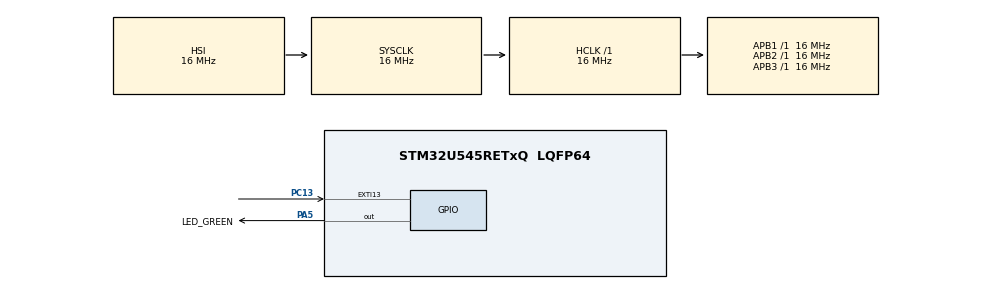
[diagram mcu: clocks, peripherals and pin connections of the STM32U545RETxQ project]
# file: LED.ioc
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CORTEX_M33_NS.userName=CORTEX_M33
Mcu.Family=STM32U5
Mcu.Name=STM32U545RETxQ
Mcu.Package=LQFP64
NVIC.EXTI13_IRQn=true\:0\:0\:false\:false\:true\:true\:true\:true
NVIC.PVD_PVM_IRQn=true\:0\:0\:false\:false\:true\:true\:true\:true
NVIC.PriorityGroup=NVIC_PRIORITYGROUP_4
NVIC.RTC_IRQn=true\:0\:0\:false\:false\:true\:true\:true\:true
PA5.GPIO_Label=LED_GREEN
PA5.GPIO_PuPd=GPIO_PULLUP
PA5.GPIO_Speed=GPIO_SPEED_FREQ_HIGH
PA5.Signal=GPIO_Output
PC13.Signal=GPXTI13
PC14-OSC32_IN\ (PC14).Mode=LSE-External-Oscillator
PC14-OSC32_IN\ (PC14).Signal=RCC_OSC32_IN
PC15-OSC32_OUT\ (PC15).Mode=LSE-External-Oscillator
PC15-OSC32_OUT\ (PC15).Signal=RCC_OSC32_OUT
PWR.PowerMode=PWR_SMPS_SUPPLY
ProjectManager.HeapSize=0x200
ProjectManager.StackSize=0x400
ProjectManager.TargetToolchain=STM32CubeIDE
RCC.ADCFreq_Value=16000000
RCC.AHBFreq_Value=16000000
RCC.APB1Freq_Value=16000000
RCC.APB1TimFreq_Value=16000000
RCC.APB2Freq_Value=16000000
RCC.APB2TimFreq_Value=16000000
RCC.APB3Freq_Value=16000000
RCC.CortexFreq_Value=16000000
RCC.DACCLockSelectionVirtual=RCC_DAC1CLKSOURCE_LSI
RCC.DACCLockSelectionVirtualString=RCC_DAC1CLKSOURCE_LSI
RCC.EPOD_VALUE=4000000
RCC.HCLKFreq_Value=16000000
RCC.HSE_VALUE=16000000
RCC.HSI48_VALUE=48000000
RCC.HSI_VALUE=16000000
RCC.LSIDIV_VALUE=32000
RCC.MSI_VALUE=4000000
RCC.RTCClockSelection=RCC_RTCCLKSOURCE_LSE
RCC.SYSCLKFreq_VALUE=16000000
RCC.SYSCLKSource=RCC_SYSCLKSOURCE_HSI
RCC.USBFreq_Value=48000000
RCC.VCOOutputFreq_Value=516000000
RTC.Alarm-Alarm\ A=RTC_ALARM_A
RTC.AlarmMaskDateWeekDay-Alarm\ A=RTC_ALARMMASK_DATEWEEKDAY
RTC.AlarmMaskHours-Alarm\ A=RTC_ALARMMASK_HOURS
RTC.AlarmMaskMinutes-Alarm\ A=RTC_ALARMMASK_MINUTES
RTC.Format=RTC_FORMAT_BCD
RTC.Seconds_A-Alarm\ A=10
RTC.rtcPrivilegeFull=RTC_PRIVILEGE_FULL_NO
VP_ICACHE_VS_ICACHE.Mode=DirectMappedCache
VP_LPBAMQUEUE_VS_QUEUE.Mode=QUEUEMODE
VP_LPBAM_VS_SIG1.Mode=SmartRun
VP_LPBAM_VS_SIG4.Mode=LPDMA1
VP_MEMORYMAP_VS_MEMORYMAP.Mode=CurAppReg
VP_PWR_VS_LPOM.Mode=PowerOptimisation
VP_PWR_VS_SECSignals.Mode=Security/Privilege
VP_RTC_VS_RTC_Activate.Mode=RTC_Enabled
VP_RTC_VS_RTC_Alarm_A_Intern.Mode=Alarm A
VP_RTC_VS_RTC_Calendar.Mode=RTC_Calendar
board=NUCLEO-U545RE-Q

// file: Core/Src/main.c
/* USER CODE BEGIN Header */
/**
 ******************************************************************************
 * @file           : main.c
 * @brief          : Main program body
 ******************************************************************************
 * @attention
 *
 * Copyright (c) 2024 STMicroelectronics.
 * All rights reserved.
 *
 * This software is licensed under terms that can be found in the LICENSE file
 * in the root directory of this software component.
 * If no LICENSE file comes with this software, it is provided AS-IS.
 *
 ******************************************************************************
 */
/* USER CODE END Header */
#include "main.h"
#include "icache.h"
#include "memorymap.h"
#include "rtc.h"
#include "gpio.h"

/* USER CODE BEGIN Includes */
#include "stdio.h"
/* USER CODE END Includes */

void SystemClock_Config(void);
static void SystemPower_Config(void);
/* USER CODE BEGIN PFP */
//void HAL_RTCEx_AlarmBEventCallback(RTC_HandleTypeDef *hrtc)
//{
//	HAL_ResumeTick();
//}
/* USER CODE END PFP */

/* USER CODE BEGIN 0 */
void Enter_Shutdown_Mode(void) {
	// Ensure all wakeup flags are cleared
	PWR->WUSCR |= PWR_WUSCR_CWUF;

	// Enable Wakeup pin (WKUP1) as wakeup source
	PWR->WUCR1 |= PWR_WUCR1_WUPEN2;

	// Select Shutdown mode in power control register
	PWR->CR1 &= ~PWR_CR1_LPMS;
	PWR->CR1 |= (0b11 << PWR_CR1_LPMS_Pos);

	// Set the SLEEPDEEP bit in Cortex System Control Register
	SCB->SCR |= SCB_SCR_SLEEPDEEP_Msk;

	// Request Wait For Interrupt
	__WFI();
}
/* USER CODE END 0 */

int main(void)
{

  /* MCU Configuration--------------------------------------------------------*/

  /* Reset of all peripherals, Initializes the Flash interface and the Systick. */
  HAL_Init();

  /* Configure the system clock */
  SystemClock_Config();

  /* Configure the System Power */
  SystemPower_Config();

  /* Initialize all configured peripherals */
  MX_GPIO_Init();
  MX_ICACHE_Init();
  MX_RTC_Init();
  /* USER CODE BEGIN 2 */

	HAL_GPIO_WritePin(LED_GREEN_GPIO_Port, LED_GREEN_Pin, SET);
	HAL_Delay(100);
	HAL_GPIO_WritePin(LED_GREEN_GPIO_Port, LED_GREEN_Pin, RESET);
	HAL_Delay(100);
	HAL_GPIO_WritePin(LED_GREEN_GPIO_Port, LED_GREEN_Pin, SET);
	HAL_Delay(100);
	HAL_GPIO_WritePin(LED_GREEN_GPIO_Port, LED_GREEN_Pin, RESET);
	HAL_Delay(100);

  /* USER CODE END 2 */

  /* Infinite loop */
	while (1) {

    /* USER CODE BEGIN 3 */
		HAL_Delay(100);
//		printf("Going to Sleep Mode\r\n");
		HAL_SuspendTick();
		Enter_Shutdown_Mode();
		HAL_ResumeTick();
		SystemClock_Config();
		HAL_Delay(100);
//		printf("Wakeup from sleep mode\r\n");
		HAL_GPIO_TogglePin(LED_GREEN_GPIO_Port, LED_GREEN_Pin);
		HAL_Delay(100);
		HAL_GPIO_TogglePin(LED_GREEN_GPIO_Port, LED_GREEN_Pin);
		HAL_Delay(100);
		HAL_GPIO_TogglePin(LED_GREEN_GPIO_Port, LED_GREEN_Pin);
		HAL_Delay(100);
		HAL_GPIO_TogglePin(LED_GREEN_GPIO_Port, LED_GREEN_Pin);
		HAL_Delay(100);
	}
  /* USER CODE END 3 */
}

void SystemClock_Config(void)
{
  RCC_OscInitTypeDef RCC_OscInitStruct = {0};
  RCC_ClkInitTypeDef RCC_ClkInitStruct = {0};

  /** Configure the main internal regulator output voltage
  */
  if (HAL_PWREx_ControlVoltageScaling(PWR_REGULATOR_VOLTAGE_SCALE4) != HAL_OK)
  {
    Error_Handler();
  }

  /** Configure LSE Drive Capability
  */
  HAL_PWR_EnableBkUpAccess();
  __HAL_RCC_LSEDRIVE_CONFIG(RCC_LSEDRIVE_LOW);

  /** Initializes the CPU, AHB and APB buses clocks
  */
  RCC_OscInitStruct.OscillatorType = RCC_OSCILLATORTYPE_HSI|RCC_OSCILLATORTYPE_LSE;
  RCC_OscInitStruct.LSEState = RCC_LSE_ON;
  RCC_OscInitStruct.HSIState = RCC_HSI_ON;
  RCC_OscInitStruct.HSICalibrationValue = RCC_HSICALIBRATION_DEFAULT;
  RCC_OscInitStruct.PLL.PLLState = RCC_PLL_NONE;
  if (HAL_RCC_OscConfig(&RCC_OscInitStruct) != HAL_OK)
  {
    Error_Handler();
  }

  /** Initializes the CPU, AHB and APB buses clocks
  */
  RCC_ClkInitStruct.ClockType = RCC_CLOCKTYPE_HCLK|RCC_CLOCKTYPE_SYSCLK
                              |RCC_CLOCKTYPE_PCLK1|RCC_CLOCKTYPE_PCLK2
                              |RCC_CLOCKTYPE_PCLK3;
  RCC_ClkInitStruct.SYSCLKSource = RCC_SYSCLKSOURCE_HSI;
  RCC_ClkInitStruct.AHBCLKDivider = RCC_SYSCLK_DIV1;
  RCC_ClkInitStruct.APB1CLKDivider = RCC_HCLK_DIV1;
  RCC_ClkInitStruct.APB2CLKDivider = RCC_HCLK_DIV1;
  RCC_ClkInitStruct.APB3CLKDivider = RCC_HCLK_DIV1;

  if (HAL_RCC_ClockConfig(&RCC_ClkInitStruct, FLASH_LATENCY_1) != HAL_OK)
  {
    Error_Handler();
  }
}

/**
  * @brief Power Configuration
  * @retval None
  */
static void SystemPower_Config(void)
{

  /*
   * Switch to SMPS regulator instead of LDO
   */
  if (HAL_PWREx_ConfigSupply(PWR_SMPS_SUPPLY) != HAL_OK)
  {
    Error_Handler();
  }
  /* PVD_PVM_IRQn interrupt configuration */
  HAL_NVIC_SetPriority(PVD_PVM_IRQn, 0, 0);
  HAL_NVIC_EnableIRQ(PVD_PVM_IRQn);
}

/* USER CODE BEGIN 4 */
void HAL_RTC_AlarmAEventCallback(RTC_HandleTypeDef *hrtc) {
	RTC_AlarmTypeDef sAlarm;
	RTC_TimeTypeDef sTime;
	RTC_DateTypeDef sDate;
	__HAL_RTC_ALARM_CLEAR_FLAG(&hrtc, RTC_FLAG_WUTF);
	HAL_RTC_GetAlarm(hrtc, &sAlarm, RTC_ALARM_A, FORMAT_BIN);
	HAL_RTC_GetTime(hrtc, &sTime, RTC_FORMAT_BIN);
	HAL_RTC_GetDate(hrtc, &sDate, RTC_FORMAT_BIN);
	if (sAlarm.AlarmTime.Seconds > 49) {
		sAlarm.AlarmTime.Seconds = (sAlarm.AlarmTime.Seconds + 10) % 60;
		sAlarm.AlarmTime.Minutes = (sAlarm.AlarmTime.Minutes + 1) % 60;
		if (sAlarm.AlarmTime.Minutes == 0) {
			sAlarm.AlarmTime.Hours = (sAlarm.AlarmTime.Hours + 1) % 24;
		}
	} else {
		sAlarm.AlarmTime.Seconds += 10;
	}
	while (HAL_RTC_SetAlarm_IT(hrtc, &sAlarm, FORMAT_BIN) != HAL_OK) {
	}
	HAL_ResumeTick();
}
/* USER CODE END 4 */

void Error_Handler(void)
{
	__disable_irq();
	while (1) {
	}
}
